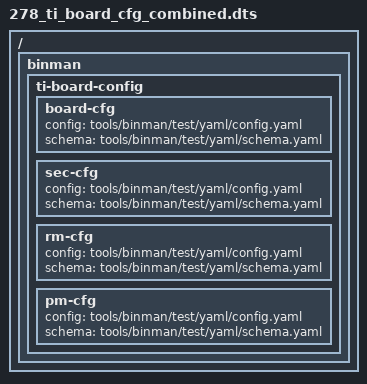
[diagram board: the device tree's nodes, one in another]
// SPDX-License-Identifier: GPL-2.0+
/dts-v1/;

/ {
	binman {
		ti-board-config {
			board-cfg {
				config = "tools/binman/test/yaml/config.yaml";
				schema = "tools/binman/test/yaml/schema.yaml";
			};
			sec-cfg {
				config = "tools/binman/test/yaml/config.yaml";
				schema = "tools/binman/test/yaml/schema.yaml";
			};
			rm-cfg {
				config = "tools/binman/test/yaml/config.yaml";
				schema = "tools/binman/test/yaml/schema.yaml";
			};
			pm-cfg {
				config = "tools/binman/test/yaml/config.yaml";
				schema = "tools/binman/test/yaml/schema.yaml";
			};
		};
	};
};
